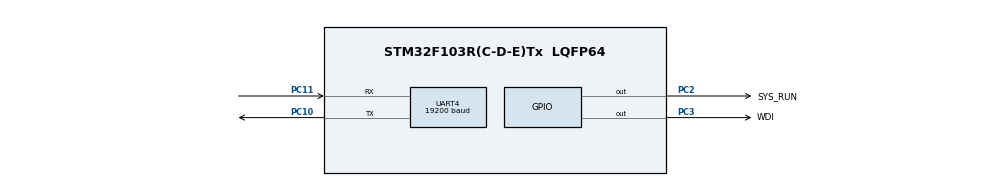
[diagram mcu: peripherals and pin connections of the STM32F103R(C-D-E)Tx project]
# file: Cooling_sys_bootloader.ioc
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Dma.Request0=UART4_RX
Dma.Request1=UART4_TX
Dma.UART4_RX.0.Direction=DMA_PERIPH_TO_MEMORY
Dma.UART4_RX.0.Instance=DMA2_Channel3
Dma.UART4_RX.0.MemDataAlignment=DMA_MDATAALIGN_BYTE
Dma.UART4_RX.0.MemInc=DMA_MINC_ENABLE
Dma.UART4_RX.0.Mode=DMA_NORMAL
Dma.UART4_RX.0.PeriphDataAlignment=DMA_PDATAALIGN_BYTE
Dma.UART4_RX.0.PeriphInc=DMA_PINC_DISABLE
Dma.UART4_RX.0.Priority=DMA_PRIORITY_LOW
Dma.UART4_TX.1.Direction=DMA_MEMORY_TO_PERIPH
Dma.UART4_TX.1.Instance=DMA2_Channel5
Dma.UART4_TX.1.MemDataAlignment=DMA_MDATAALIGN_BYTE
Dma.UART4_TX.1.MemInc=DMA_MINC_ENABLE
Dma.UART4_TX.1.Mode=DMA_NORMAL
Dma.UART4_TX.1.PeriphDataAlignment=DMA_PDATAALIGN_BYTE
Dma.UART4_TX.1.PeriphInc=DMA_PINC_DISABLE
Dma.UART4_TX.1.Priority=DMA_PRIORITY_LOW
FREERTOS.Tasks01=defaultTask,24,128,StartDefaultTask,Default,NULL,Dynamic,NULL,NULL;myTask_led,8,128,led,Default,NULL,Dynamic,NULL,NULL;myTask_uart_rx,8,128,uart_rx,Default,NULL,Dynamic,NULL,NULL;myTask_uart_tx,8,128,uart_tx,Default,NULL,Dynamic,NULL,NULL
Mcu.Family=STM32F1
Mcu.Name=STM32F103R(C-D-E)Tx
Mcu.Package=LQFP64
NVIC.DMA2_Channel3_IRQn=true\:5\:0\:false\:false\:true\:true\:false\:true\:true
NVIC.DMA2_Channel4_5_IRQn=true\:5\:0\:false\:false\:true\:true\:false\:true\:true
NVIC.PriorityGroup=NVIC_PRIORITYGROUP_4
NVIC.TIM7_IRQn=true\:15\:0\:false\:false\:true\:false\:false\:true\:true
NVIC.TimeBase=TIM7_IRQn
NVIC.TimeBaseIP=TIM7
NVIC.UART4_IRQn=true\:10\:0\:true\:false\:true\:true\:true\:true\:true
PA13.Mode=Serial_Wire
PA13.Signal=SYS_JTMS-SWDIO
PA14.Mode=Serial_Wire
PA14.Signal=SYS_JTCK-SWCLK
PC10.Mode=Asynchronous
PC10.Signal=UART4_TX
PC11.Mode=Asynchronous
PC11.Signal=UART4_RX
PC14-OSC32_IN.Mode=LSE-External-Oscillator
PC14-OSC32_IN.Signal=RCC_OSC32_IN
PC15-OSC32_OUT.Mode=LSE-External-Oscillator
PC15-OSC32_OUT.Signal=RCC_OSC32_OUT
PC2.GPIO_Label=SYS_RUN
PC2.Signal=GPIO_Output
PC3.GPIO_Label=WDI
PC3.Signal=GPIO_Output
PD0-OSC_IN.Mode=HSE-External-Oscillator
PD0-OSC_IN.Signal=RCC_OSC_IN
PD1-OSC_OUT.Mode=HSE-External-Oscillator
PD1-OSC_OUT.Signal=RCC_OSC_OUT
ProjectManager.HeapSize=0x200
ProjectManager.StackSize=0x400
ProjectManager.TargetToolchain=MDK-ARM V5.32
RCC.APB1Freq_Value=8000000
RCC.APB2Freq_Value=8000000
UART4.BaudRate=19200
UART4.Parity=PARITY_NONE
UART4.VirtualMode=Asynchronous
UART4.WordLength=WORDLENGTH_8B
VP_FREERTOS_VS_CMSIS_V2.Mode=CMSIS_V2
VP_SYS_VS_tim7.Mode=TIM7
board=custom

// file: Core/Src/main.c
/* USER CODE BEGIN Header */
/**
  ******************************************************************************
  * @file           : main.c
  * @brief          : Main program body
  ******************************************************************************
  * @attention
  *
  * Copyright (c) 2026 STMicroelectronics.
  * All rights reserved.
  *
  * This software is licensed under terms that can be found in the LICENSE file
  * in the root directory of this software component.
  * If no LICENSE file comes with this software, it is provided AS-IS.
  *
  ******************************************************************************
  */
/* USER CODE END Header */
#include "main.h"
#include "cmsis_os.h"
#include "dma.h"
#include "usart.h"
#include "gpio.h"

/* USER CODE BEGIN Includes */
# include "string.h"
//#include "Int_bootloader.h"
#include "app_bootloader.h"

/* USER CODE END Includes */

void SystemClock_Config(void);
void MX_FREERTOS_Init(void);

int main(void)
{

  /* MCU Configuration--------------------------------------------------------*/

  /* Reset of all peripherals, Initializes the Flash interface and the Systick. */
  HAL_Init();

  /* Configure the system clock */
  SystemClock_Config();

  /* Initialize all configured peripherals */
  MX_GPIO_Init();
  MX_DMA_Init();
  MX_UART4_Init();
  /* USER CODE BEGIN 2 */
  //Int_bootloader_init();

  //测试应用层逻辑
  App_bootloader_init();

  /* USER CODE END 2 */

  /* Init scheduler */
  osKernelInitialize();

  /* Call init function for freertos objects (in cmsis_os2.c) */
  MX_FREERTOS_Init();

  /* Start scheduler */
  osKernelStart();

  /* We should never get here as control is now taken by the scheduler */

  /* Infinite loop */
  /* USER CODE BEGIN WHILE */
  while (1)
  {
    osDelay(1);
    //Int_bootloader_jump_to_app();  //测试跳转到应用程序
    //App_bootloader_work();  //测试bootloader的工作流程
    /* USER CODE END WHILE */

  }
}

void SystemClock_Config(void)
{
  RCC_OscInitTypeDef RCC_OscInitStruct = {0};
  RCC_ClkInitTypeDef RCC_ClkInitStruct = {0};

  /** Initializes the RCC Oscillators according to the specified parameters
  * in the RCC_OscInitTypeDef structure.
  */
  RCC_OscInitStruct.OscillatorType = RCC_OSCILLATORTYPE_HSI;
  RCC_OscInitStruct.HSIState = RCC_HSI_ON;
  RCC_OscInitStruct.HSICalibrationValue = RCC_HSICALIBRATION_DEFAULT;
  RCC_OscInitStruct.PLL.PLLState = RCC_PLL_NONE;
  if (HAL_RCC_OscConfig(&RCC_OscInitStruct) != HAL_OK)
  {
    Error_Handler();
  }

  /** Initializes the CPU, AHB and APB buses clocks
  */
  RCC_ClkInitStruct.ClockType = RCC_CLOCKTYPE_HCLK|RCC_CLOCKTYPE_SYSCLK
                              |RCC_CLOCKTYPE_PCLK1|RCC_CLOCKTYPE_PCLK2;
  RCC_ClkInitStruct.SYSCLKSource = RCC_SYSCLKSOURCE_HSI;
  RCC_ClkInitStruct.AHBCLKDivider = RCC_SYSCLK_DIV1;
  RCC_ClkInitStruct.APB1CLKDivider = RCC_HCLK_DIV1;
  RCC_ClkInitStruct.APB2CLKDivider = RCC_HCLK_DIV1;

  if (HAL_RCC_ClockConfig(&RCC_ClkInitStruct, FLASH_LATENCY_0) != HAL_OK)
  {
    Error_Handler();
  }
}

void HAL_TIM_PeriodElapsedCallback(TIM_HandleTypeDef *htim)
{
  if (htim->Instance == TIM7) {
    HAL_IncTick();
  }
}

void Error_Handler(void)
{
  __disable_irq();
  while (1)
  {
  }
}

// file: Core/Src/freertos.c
/* USER CODE BEGIN Header */
/**
  ******************************************************************************
  * File Name          : freertos.c
  * Description        : Code for freertos applications
  ******************************************************************************
  * @attention
  *
  * Copyright (c) 2026 STMicroelectronics.
  * All rights reserved.
  *
  * This software is licensed under terms that can be found in the LICENSE file
  * in the root directory of this software component.
  * If no LICENSE file comes with this software, it is provided AS-IS.
  *
  ******************************************************************************
  */
/* USER CODE END Header */

#include "FreeRTOS.h"
#include "task.h"
#include "main.h"
#include "cmsis_os.h"

/* USER CODE BEGIN Includes */
#include "usart.h"
#include "Int_bootloader.h"
/* USER CODE END Includes */

/* USER CODE BEGIN PTD */
//#define REC_BUFF_LEN 512
/* USER CODE END PTD */

/* USER CODE BEGIN Variables */
 //uint8_t receive_buff[REC_BUFF_LEN] =  {0};
 uint16_t receive_len = 0;
 extern uint16_t uart_rec_full_len;
/* USER CODE END Variables */
/* Definitions for defaultTask */
osThreadId_t defaultTaskHandle;
const osThreadAttr_t defaultTask_attributes = {
  .name = "defaultTask",
  .stack_size = 128 * 4,
  .priority = (osPriority_t) osPriorityNormal,
};
/* Definitions for myTask_led */
osThreadId_t myTask_ledHandle;
const osThreadAttr_t myTask_led_attributes = {
  .name = "myTask_led",
  .stack_size = 128 * 4,
  .priority = (osPriority_t) osPriorityLow,
};
/* Definitions for myTask_uart_rx */
osThreadId_t myTask_uart_rxHandle;
const osThreadAttr_t myTask_uart_rx_attributes = {
  .name = "myTask_uart_rx",
  .stack_size = 128 * 4,
  .priority = (osPriority_t) osPriorityLow,
};
/* Definitions for myTask_uart_tx */
osThreadId_t myTask_uart_txHandle;
const osThreadAttr_t myTask_uart_tx_attributes = {
  .name = "myTask_uart_tx",
  .stack_size = 128 * 4,
  .priority = (osPriority_t) osPriorityLow,
};

void StartDefaultTask(void *argument);
void led(void *argument);
void uart_rx(void *argument);
void uart_tx(void *argument);

void MX_FREERTOS_Init(void); /* (MISRA C 2004 rule 8.1) */

void MX_FREERTOS_Init(void) {

  /* Create the thread(s) */
  /* creation of defaultTask */
  defaultTaskHandle = osThreadNew(StartDefaultTask, NULL, &defaultTask_attributes);

  /* creation of myTask_led */
  myTask_ledHandle = osThreadNew(led, NULL, &myTask_led_attributes);

  /* creation of myTask_uart_rx */
  myTask_uart_rxHandle = osThreadNew(uart_rx, NULL, &myTask_uart_rx_attributes);

  /* creation of myTask_uart_tx */
  myTask_uart_txHandle = osThreadNew(uart_tx, NULL, &myTask_uart_tx_attributes);

}

void StartDefaultTask(void *argument)
{
  /* USER CODE BEGIN StartDefaultTask */
  /* Infinite loop */
  for(;;)
  {
    osDelay(3000);
		App_bootloader_work();
  }
  /* USER CODE END StartDefaultTask */
}

void led(void *argument)
{
  /* USER CODE BEGIN led */
  //NonBlockingDelay_t ledDelay;
	//nonBlockingDelay_Init(&ledDelay, 500); // 500ms延时
  /* Infinite loop */
  for(;;)
  {
    //osDelay(1);
    HAL_GPIO_TogglePin(SYS_RUN_GPIO_Port, SYS_RUN_Pin);                            	//  系统运行指示灯
		HAL_GPIO_TogglePin(WDI_GPIO_Port, WDI_Pin);	                                    //  喂狗
		osDelay(500);
	}
  //}
  /* USER CODE END led */
}

void uart_rx(void *argument)
{
  /* USER CODE BEGIN uart_rx */

  /* Infinite loop */
  for(;;)
  {
    osDelay(1);
    //HAL_UART_Receive(&huart4, receive_buff, REC_BUFF_LEN , 0xffffff );
    //HAL_UARTEx_ReceiveToIdle(&huart4,receive_buff,REC_BUFF_LEN,&receive_len,0xffffff);
    //if(receive_len > 0)
    //{
      //HAL_UART_Transmit(&huart4, receive_buff, strlen((char *)receive_buff), 1000);
      //memset(receive_buff, 0, REC_BUFF_LEN);
      //receive_len = 0;
    //}
  }
  /* USER CODE END uart_rx */
}

void uart_tx(void *argument)
{
  /* USER CODE BEGIN uart_tx */
  /* Infinite loop */
  for(;;)
  {
    osDelay(1);
    //osDelay(3000);
    //printf("buff: %d", uart_rec_full_len);   ///

  }
  /* USER CODE END uart_tx */
}
